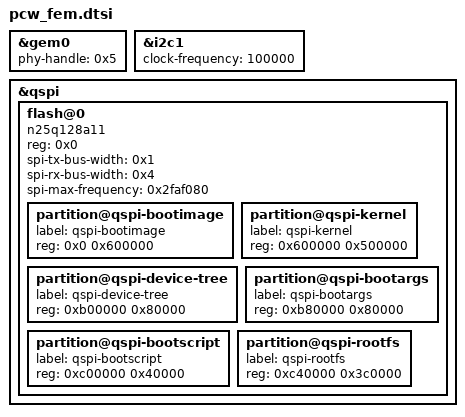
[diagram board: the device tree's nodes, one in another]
&gem0 {
	phy-handle = <0x5>;
};
&i2c1 {
	clock-frequency = <100000>;
};
&qspi {
flash@0 {
compatible = "n25q128a11";
reg = <0x0>;
spi-tx-bus-width = <0x1>;
spi-rx-bus-width = <0x4>;
spi-max-frequency = <0x2faf080>;
#address-cells = <0x1>;
#size-cells = <0x1>;

partition@qspi-bootimage {
label = "qspi-bootimage";
reg = <0x0 0x600000>;
};

partition@qspi-kernel {
label = "qspi-kernel";
reg = <0x600000 0x500000>;
};

partition@qspi-device-tree {
label = "qspi-device-tree";
reg = <0xb00000 0x80000>;
};

partition@qspi-bootargs {
label = "qspi-bootargs";
reg = <0xb80000 0x80000>;
};

partition@qspi-bootscript {
label = "qspi-bootscript";
reg = <0xc00000 0x40000>;
};

partition@qspi-rootfs {
label = "qspi-rootfs";
reg = <0xc40000 0x3c0000>;
};
};
};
